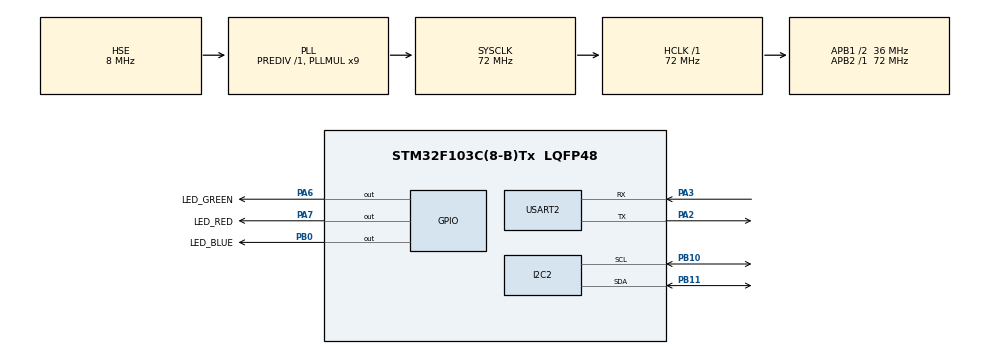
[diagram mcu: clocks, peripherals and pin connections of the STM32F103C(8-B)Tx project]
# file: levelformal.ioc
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Dma.Request0=USART2_RX
Dma.Request1=USART2_TX
Dma.USART2_RX.0.Direction=DMA_PERIPH_TO_MEMORY
Dma.USART2_RX.0.Instance=DMA1_Channel6
Dma.USART2_RX.0.MemDataAlignment=DMA_MDATAALIGN_BYTE
Dma.USART2_RX.0.MemInc=DMA_MINC_ENABLE
Dma.USART2_RX.0.Mode=DMA_NORMAL
Dma.USART2_RX.0.PeriphDataAlignment=DMA_PDATAALIGN_BYTE
Dma.USART2_RX.0.PeriphInc=DMA_PINC_DISABLE
Dma.USART2_RX.0.Priority=DMA_PRIORITY_LOW
Dma.USART2_TX.1.Direction=DMA_MEMORY_TO_PERIPH
Dma.USART2_TX.1.Instance=DMA1_Channel7
Dma.USART2_TX.1.MemDataAlignment=DMA_MDATAALIGN_BYTE
Dma.USART2_TX.1.MemInc=DMA_MINC_ENABLE
Dma.USART2_TX.1.Mode=DMA_NORMAL
Dma.USART2_TX.1.PeriphDataAlignment=DMA_PDATAALIGN_BYTE
Dma.USART2_TX.1.PeriphInc=DMA_PINC_DISABLE
Dma.USART2_TX.1.Priority=DMA_PRIORITY_LOW
FREERTOS.BinarySemaphores01=uartTxDone,Dynamic,NULL,Available
FREERTOS.Mutexes01=i2cMutex,Dynamic,NULL,Available
FREERTOS.Queues01=attitudeQueue,1,AttitudeMsg_t,0,Dynamic,NULL,NULL;uartFrameQueue,4,UartFrame_t,0,Dynamic,NULL,NULL
FREERTOS.Tasks01=defaultTask,24,128,StartDefaultTask,Default,NULL,Dynamic,NULL,NULL;IMU,40,256,AppImu_Task,As external,NULL,Dynamic,NULL,NULL;UART,32,256,AppUart_Task,As external,NULL,Dynamic,NULL,NULL;DISP,8,256,AppDisplay_Task,As external,NULL,Dynamic,NULL,NULL
FREERTOS.configTOTAL_HEAP_SIZE=8192
I2C2.I2C_Mode=I2C_Fast
Mcu.Family=STM32F1
Mcu.Name=STM32F103C(8-B)Tx
Mcu.Package=LQFP48
NVIC.DMA1_Channel6_IRQn=true\:5\:0\:false\:false\:true\:true\:false\:true\:true
NVIC.DMA1_Channel7_IRQn=true\:5\:0\:false\:false\:true\:true\:false\:true\:true
NVIC.PriorityGroup=NVIC_PRIORITYGROUP_4
NVIC.TIM4_IRQn=true\:15\:0\:false\:false\:true\:false\:false\:true\:true
NVIC.TimeBase=TIM4_IRQn
NVIC.TimeBaseIP=TIM4
NVIC.USART2_IRQn=true\:5\:0\:false\:false\:true\:true\:false\:true\:true
PA13.Mode=Serial_Wire
PA13.Signal=SYS_JTMS-SWDIO
PA14.Mode=Serial_Wire
PA14.Signal=SYS_JTCK-SWCLK
PA2.Mode=Asynchronous
PA2.Signal=USART2_TX
PA3.Mode=Asynchronous
PA3.Signal=USART2_RX
PA6.GPIO_Label=LED_GREEN
PA6.Signal=GPIO_Output
PA7.GPIO_Label=LED_RED
PA7.Signal=GPIO_Output
PB0.GPIO_Label=LED_BLUE
PB0.Signal=GPIO_Output
PB10.Mode=I2C
PB10.Signal=I2C2_SCL
PB11.Mode=I2C
PB11.Signal=I2C2_SDA
PD0-OSC_IN.Mode=HSE-External-Oscillator
PD0-OSC_IN.Signal=RCC_OSC_IN
PD1-OSC_OUT.Mode=HSE-External-Oscillator
PD1-OSC_OUT.Signal=RCC_OSC_OUT
ProjectManager.HeapSize=0x200
ProjectManager.StackSize=0x400
ProjectManager.TargetToolchain=MDK-ARM V5.32
RCC.AHBFreq_Value=72000000
RCC.APB1CLKDivider=RCC_HCLK_DIV2
RCC.APB1Freq_Value=36000000
RCC.APB1TimFreq_Value=72000000
RCC.APB2Freq_Value=72000000
RCC.APB2TimFreq_Value=72000000
RCC.EnbaleCSS=true
RCC.HCLKFreq_Value=72000000
RCC.PLLMUL=RCC_PLL_MUL9
RCC.PLLSourceVirtual=RCC_PLLSOURCE_HSE
RCC.SYSCLKFreq_VALUE=72000000
RCC.SYSCLKSource=RCC_SYSCLKSOURCE_PLLCLK
RCC.USBFreq_Value=72000000
USART2.VirtualMode=VM_ASYNC
VP_FREERTOS_VS_CMSIS_V2.Mode=CMSIS_V2
VP_SYS_VS_tim4.Mode=TIM4
board=custom

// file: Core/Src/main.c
/* USER CODE BEGIN Header */
/**
  ******************************************************************************
  * @file           : main.c
  * @brief          : Main program body
  ******************************************************************************
  * @attention
  *
  * Copyright (c) 2026 STMicroelectronics.
  * All rights reserved.
  *
  * This software is licensed under terms that can be found in the LICENSE file
  * in the root directory of this software component.
  * If no LICENSE file comes with this software, it is provided AS-IS.
  *
  ******************************************************************************
  */
/* USER CODE END Header */
#include "main.h"
#include "cmsis_os.h"
#include "dma.h"
#include "i2c.h"
#include "usart.h"
#include "gpio.h"

void SystemClock_Config(void);
void MX_FREERTOS_Init(void);

int main(void)
{

  /* MCU Configuration--------------------------------------------------------*/

  /* Reset of all peripherals, Initializes the Flash interface and the Systick. */
  HAL_Init();

  /* Configure the system clock */
  SystemClock_Config();

  /* Initialize all configured peripherals */
  MX_GPIO_Init();
  MX_DMA_Init();
  MX_USART2_UART_Init();
  MX_I2C2_Init();

  /* Init scheduler */
  osKernelInitialize();  /* Call init function for freertos objects (in cmsis_os2.c) */
  MX_FREERTOS_Init();

  /* Start scheduler */
  osKernelStart();

  /* We should never get here as control is now taken by the scheduler */

  /* Infinite loop */
  while (1)
  {

  }
}

void SystemClock_Config(void)
{
  RCC_OscInitTypeDef RCC_OscInitStruct = {0};
  RCC_ClkInitTypeDef RCC_ClkInitStruct = {0};

  /** Initializes the RCC Oscillators according to the specified parameters
  * in the RCC_OscInitTypeDef structure.
  */
  RCC_OscInitStruct.OscillatorType = RCC_OSCILLATORTYPE_HSE;
  RCC_OscInitStruct.HSEState = RCC_HSE_ON;
  RCC_OscInitStruct.HSEPredivValue = RCC_HSE_PREDIV_DIV1;
  RCC_OscInitStruct.HSIState = RCC_HSI_ON;
  RCC_OscInitStruct.PLL.PLLState = RCC_PLL_ON;
  RCC_OscInitStruct.PLL.PLLSource = RCC_PLLSOURCE_HSE;
  RCC_OscInitStruct.PLL.PLLMUL = RCC_PLL_MUL9;
  if (HAL_RCC_OscConfig(&RCC_OscInitStruct) != HAL_OK)
  {
    Error_Handler();
  }

  /** Initializes the CPU, AHB and APB buses clocks
  */
  RCC_ClkInitStruct.ClockType = RCC_CLOCKTYPE_HCLK|RCC_CLOCKTYPE_SYSCLK
                              |RCC_CLOCKTYPE_PCLK1|RCC_CLOCKTYPE_PCLK2;
  RCC_ClkInitStruct.SYSCLKSource = RCC_SYSCLKSOURCE_PLLCLK;
  RCC_ClkInitStruct.AHBCLKDivider = RCC_SYSCLK_DIV1;
  RCC_ClkInitStruct.APB1CLKDivider = RCC_HCLK_DIV2;
  RCC_ClkInitStruct.APB2CLKDivider = RCC_HCLK_DIV1;

  if (HAL_RCC_ClockConfig(&RCC_ClkInitStruct, FLASH_LATENCY_2) != HAL_OK)
  {
    Error_Handler();
  }

  /** Enables the Clock Security System
  */
  HAL_RCC_EnableCSS();
}

void HAL_TIM_PeriodElapsedCallback(TIM_HandleTypeDef *htim)
{
  if (htim->Instance == TIM4)
  {
    HAL_IncTick();
  }
}

void Error_Handler(void)
{
  __disable_irq();
  while (1)
  {
  }
}

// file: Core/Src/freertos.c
/* USER CODE BEGIN Header */
/**
  ******************************************************************************
  * File Name          : freertos.c
  * Description        : Code for freertos applications
  ******************************************************************************
  * @attention
  *
  * Copyright (c) 2026 STMicroelectronics.
  * All rights reserved.
  *
  * This software is licensed under terms that can be found in the LICENSE file
  * in the root directory of this software component.
  * If no LICENSE file comes with this software, it is provided AS-IS.
  *
  ******************************************************************************
  */
/* USER CODE END Header */

#include "FreeRTOS.h"
#include "task.h"
#include "main.h"
#include "cmsis_os2.h"

/* USER CODE BEGIN Includes */
#include "app_common.h"
/* USER CODE END Includes */

/* Definitions for defaultTask */
osThreadId_t defaultTaskHandle;
const osThreadAttr_t defaultTask_attributes = {
  .name = "defaultTask",
  .stack_size = 128 * 4,
  .priority = (osPriority_t) osPriorityNormal,
};
/* Definitions for IMU */
osThreadId_t IMUHandle;
const osThreadAttr_t IMU_attributes = {
  .name = "IMU",
  .stack_size = 256 * 4,
  .priority = (osPriority_t) osPriorityHigh,
};
/* Definitions for UART */
osThreadId_t UARTHandle;
const osThreadAttr_t UART_attributes = {
  .name = "UART",
  .stack_size = 256 * 4,
  .priority = (osPriority_t) osPriorityAboveNormal,
};
/* Definitions for DISP */
osThreadId_t DISPHandle;
const osThreadAttr_t DISP_attributes = {
  .name = "DISP",
  .stack_size = 256 * 4,
  .priority = (osPriority_t) osPriorityLow,
};
/* Definitions for attitudeQueue */
osMessageQueueId_t attitudeQueueHandle;
const osMessageQueueAttr_t attitudeQueue_attributes = {
  .name = "attitudeQueue"
};
/* Definitions for uartFrameQueue */
osMessageQueueId_t uartFrameQueueHandle;
const osMessageQueueAttr_t uartFrameQueue_attributes = {
  .name = "uartFrameQueue"
};
/* Definitions for i2cMutex */
osMutexId_t i2cMutexHandle;
const osMutexAttr_t i2cMutex_attributes = {
  .name = "i2cMutex"
};
/* Definitions for uartTxDone */
osSemaphoreId_t uartTxDoneHandle;
const osSemaphoreAttr_t uartTxDone_attributes = {
  .name = "uartTxDone"
};

void StartDefaultTask(void *argument);
extern void AppImu_Task(void *argument);
extern void AppUart_Task(void *argument);
extern void AppDisplay_Task(void *argument);

void MX_FREERTOS_Init(void); /* (MISRA C 2004 rule 8.1) */

void MX_FREERTOS_Init(void) {
  /* Create the mutex(es) */
  /* creation of i2cMutex */
  i2cMutexHandle = osMutexNew(&i2cMutex_attributes);

  /* Create the semaphores(s) */
  /* creation of uartTxDone */
  uartTxDoneHandle = osSemaphoreNew(1, 1, &uartTxDone_attributes);

  /* Create the queue(s) */
  /* creation of attitudeQueue */
  attitudeQueueHandle = osMessageQueueNew (1, sizeof(AttitudeMsg_t), &attitudeQueue_attributes);

  /* creation of uartFrameQueue */
  uartFrameQueueHandle = osMessageQueueNew (4, sizeof(UartFrame_t), &uartFrameQueue_attributes);

  /* Create the thread(s) */
  /* creation of defaultTask */
  defaultTaskHandle = osThreadNew(StartDefaultTask, NULL, &defaultTask_attributes);

  /* creation of IMU */
  IMUHandle = osThreadNew(AppImu_Task, NULL, &IMU_attributes);

  /* creation of UART */
  UARTHandle = osThreadNew(AppUart_Task, NULL, &UART_attributes);

  /* creation of DISP */
  DISPHandle = osThreadNew(AppDisplay_Task, NULL, &DISP_attributes);

}

void StartDefaultTask(void *argument)
{
  for(;;)
  {
    osDelay(1);
  }
}
